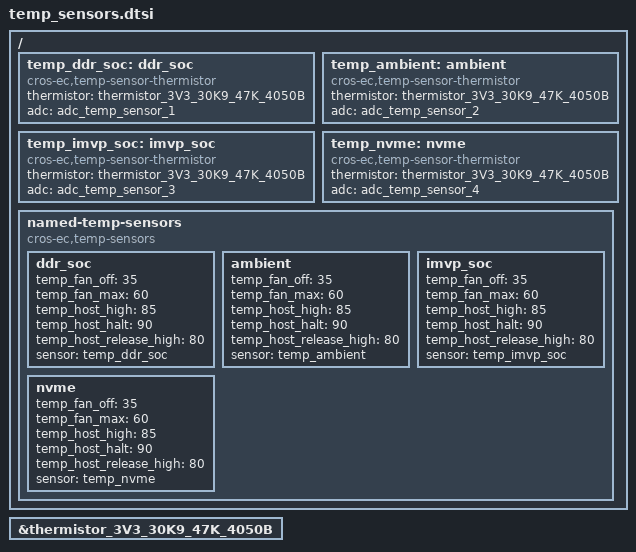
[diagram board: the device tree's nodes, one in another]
/* Copyright 2024 The ChromiumOS Authors
 * Use of this source code is governed by a BSD-style license that can be
 * found in the LICENSE file.
 */

#include <cros/thermistor/thermistor.dtsi>

/ {
	temp_ddr_soc: ddr_soc {
		compatible = "cros-ec,temp-sensor-thermistor";
		thermistor = <&thermistor_3V3_30K9_47K_4050B>;
		adc = <&adc_temp_sensor_1>;
	};
	temp_ambient: ambient {
		compatible = "cros-ec,temp-sensor-thermistor";
		thermistor = <&thermistor_3V3_30K9_47K_4050B>;
		adc = <&adc_temp_sensor_2>;
	};
	temp_imvp_soc: imvp_soc {
		compatible = "cros-ec,temp-sensor-thermistor";
		thermistor = <&thermistor_3V3_30K9_47K_4050B>;
		adc = <&adc_temp_sensor_3>;
	};
	temp_nvme: nvme {
		compatible = "cros-ec,temp-sensor-thermistor";
		thermistor = <&thermistor_3V3_30K9_47K_4050B>;
		adc = <&adc_temp_sensor_4>;
	};

	named-temp-sensors {
		compatible = "cros-ec,temp-sensors";
		ddr_soc {
			temp_fan_off = <35>;
			temp_fan_max = <60>;
			temp_host_high = <85>;
			temp_host_halt = <90>;
			temp_host_release_high = <80>;
			sensor = <&temp_ddr_soc>;
		};
		ambient {
			temp_fan_off = <35>;
			temp_fan_max = <60>;
			temp_host_high = <85>;
			temp_host_halt = <90>;
			temp_host_release_high = <80>;
			sensor = <&temp_ambient>;
		};
		imvp_soc {
			temp_fan_off = <35>;
			temp_fan_max = <60>;
			temp_host_high = <85>;
			temp_host_halt = <90>;
			temp_host_release_high = <80>;
			sensor = <&temp_imvp_soc>;
		};
		nvme {
			temp_fan_off = <35>;
			temp_fan_max = <60>;
			temp_host_high = <85>;
			temp_host_halt = <90>;
			temp_host_release_high = <80>;
			sensor = <&temp_nvme>;
		};
	};
};

&thermistor_3V3_30K9_47K_4050B {
	status = "okay";
};
